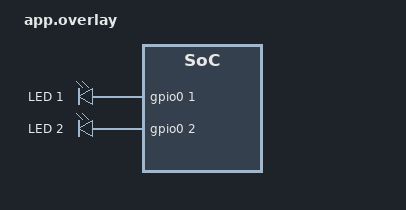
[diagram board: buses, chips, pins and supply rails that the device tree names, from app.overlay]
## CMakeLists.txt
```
# SPDX-License-Identifier: Apache-2.0

cmake_minimum_required(VERSION 3.28.0)

find_package(Zephyr REQUIRED HINTS $ENV{ZEPHYR_BASE})
project(projeto)

target_sources(app PRIVATE
	src/main.c
	src/led.c
)
```

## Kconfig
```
menu "LEDs"

config BLINK_SLOW_MS
	int "Periodo do pisca lento (ms)"
	default 1000

config BLINK_NORMAL_MS
	int "Periodo do pisca normal (ms)"
	default 400

config BLINK_FAST_MS
	int "Periodo do pisca rapido (ms)"
	default 100

endmenu

source "Kconfig.zephyr"
```

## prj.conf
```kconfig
CONFIG_GPIO=y
CONFIG_GPIO_EMUL=y
CONFIG_LOG=y
```

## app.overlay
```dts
/* led1 e led2 no gpio0, junto do led0 que ja vem na placa */

#include <zephyr/dt-bindings/gpio/gpio.h>

&leds {
	led1: led_1 {
		gpios = <&gpio0 1 GPIO_ACTIVE_HIGH>;
		label = "LED 1";
	};

	led2: led_2 {
		gpios = <&gpio0 2 GPIO_ACTIVE_HIGH>;
		label = "LED 2";
	};
};

/ {
	aliases {
		led1 = &led1;
		led2 = &led2;
	};
};
```

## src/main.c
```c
/*******************************************************************
 * @file main.c
 *
 * @brief Main file.
 * @author João Matheus Nascimento Dias (jmnd@ic.ufal.br)
 * @author Erick Mascarenhas (edlm@ic.ufal.br)
 * @version 0.1
 * @date 21/10/2026
 *******************************************************************/

#include <zephyr/kernel.h>
#include <zephyr/logging/log.h>

#include "led.h"

LOG_MODULE_REGISTER(main, CONFIG_LOG_DEFAULT_LEVEL);

int main(void)
{
	int ret;

	ret = led_init();
	if (ret < 0) {
		LOG_ERR("led_init falhou (%d)", ret);
		return 0;
	}

	LOG_INF("%zu LEDs prontos", led_count());

	ret = led_blink(0U, LED_PATTERN_SLOW);
	if (ret < 0) {
		LOG_ERR("led_blink(0) falhou (%d)", ret);
		return 0;
	}

	ret = led_blink(1U, LED_PATTERN_FAST);
	if (ret < 0) {
		LOG_ERR("led_blink(1) falhou (%d)", ret);
		return 0;
	}

	ret = led_on(2U);
	if (ret < 0) {
		LOG_ERR("led_on(2) falhou (%d)", ret);
		return 0;
	}

	LOG_INF("led0 lento, led1 rapido, led2 aceso");

	return 0;
}
```

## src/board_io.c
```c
/*******************************************************************
 * @file board_io.c
 *
 * @brief LED e botao da placa, obtidos do devicetree.
 * @author Erick Mascarenhas (edlm@ic.ufal.br)
 * @version 0.1
 * @date 21/10/2026
 *******************************************************************/

#include <errno.h>
#include <stdbool.h>

#include <zephyr/drivers/gpio.h>

#include "board_io.h"

static const struct gpio_dt_spec led = GPIO_DT_SPEC_GET(DT_ALIAS(led0), gpios);
static const struct gpio_dt_spec button = GPIO_DT_SPEC_GET(DT_ALIAS(sw0), gpios);

/* Guarda o estado do LED, ja que ler um pino de saida depende do driver */
static bool led_is_on;

int board_io_init(void)
{
	int ret;

	if (!gpio_is_ready_dt(&led) || !gpio_is_ready_dt(&button)) {
		return -ENODEV;
	}

	ret = gpio_pin_configure_dt(&led, GPIO_OUTPUT_INACTIVE);
	if (ret < 0) {
		return ret;
	}

	ret = gpio_pin_configure_dt(&button, GPIO_INPUT);
	if (ret < 0) {
		return ret;
	}

	led_is_on = false;

	return 0;
}

int board_io_led_set(bool on)
{
	int ret = gpio_pin_set_dt(&led, on);

	if (ret < 0) {
		return ret;
	}

	led_is_on = on;

	return 0;
}

bool board_io_led_get(void)
{
	return led_is_on;
}

int board_io_button_get(void)
{
	return gpio_pin_get_dt(&button);
}
```

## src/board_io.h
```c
/*******************************************************************
 * @file board_io.h
 *
 * @brief LED e botao da placa.
 * @author Erick Mascarenhas (edlm@ic.ufal.br)
 * @version 0.1
 * @date 21/10/2026
 *******************************************************************/

#ifndef BOARD_IO_H_
#define BOARD_IO_H_

#include <stdbool.h>

int board_io_init(void);
int board_io_led_set(bool on);
bool board_io_led_get(void);

/* 1 pressionado, 0 solto ou erro negativo */
int board_io_button_get(void);

#endif /* BOARD_IO_H_ */
```

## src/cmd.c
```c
/*******************************************************************
 * @file cmd.c
 *
 * @brief Interpretacao e despacho dos comandos da shell.
 * @author Erick Mascarenhas (edlm@ic.ufal.br)
 * @version 0.1
 * @date 21/10/2026
 *******************************************************************/

#include <errno.h>
#include <stdbool.h>
#include <stddef.h>
#include <stdio.h>

#include <zephyr/kernel.h>
#include <zephyr/sys/util.h>

#include "board_io.h"
#include "cmd.h"

typedef struct {
	const char *name;
	const char *usage;
	void (*handler)(const char *args, char *out, size_t out_size);
} cmd_entry_t;

static void cmd_help(const char *args, char *out, size_t out_size);
static void cmd_led(const char *args, char *out, size_t out_size);
static void cmd_btn(const char *args, char *out, size_t out_size);
static void cmd_uptime(const char *args, char *out, size_t out_size);
static void cmd_echo(const char *args, char *out, size_t out_size);

static const cmd_entry_t commands[] = {
	{.name = "HELP", .usage = "HELP - lista os comandos", .handler = cmd_help},
	{.name = "LED",
	 .usage = "LED [ON|OFF] - liga, desliga ou consulta o LED",
	 .handler = cmd_led},
	{.name = "BTN", .usage = "BTN - le o botao", .handler = cmd_btn},
	{.name = "UPTIME", .usage = "UPTIME - tempo desde o boot, em ms", .handler = cmd_uptime},
	{.name = "ECHO", .usage = "ECHO <texto> - devolve o texto", .handler = cmd_echo},
};

static char to_upper(char c)
{
	return ((c >= 'a') && (c <= 'z')) ? (char)(c - 'a' + 'A') : c;
}

static bool is_space(char c)
{
	return (c == ' ') || (c == '\t');
}

static const char *skip_spaces(const char *s)
{
	while (is_space(*s)) {
		s++;
	}

	return s;
}

static size_t token_len(const char *s)
{
	size_t n = 0U;

	while ((s[n] != '\0') && !is_space(s[n])) {
		n++;
	}

	return n;
}

/* compara sem diferenciar maiusculas, name ja vem em maiusculas */
static bool token_equals(const char *token, size_t len, const char *name)
{
	for (size_t i = 0U; i < len; i++) {
		if (to_upper(token[i]) != name[i]) {
			return false;
		}
	}

	return name[len] == '\0';
}

static void respond(char *out, size_t out_size, const char *text)
{
	(void)snprintf(out, out_size, "%s", text);
}

static void cmd_help(const char *args, char *out, size_t out_size)
{
	size_t used = 0U;

	ARG_UNUSED(args);

	for (size_t i = 0U; i < ARRAY_SIZE(commands); i++) {
		int written = snprintf(&out[used], out_size - used, "%s%s", (i == 0U) ? "" : "\r\n",
				       commands[i].usage);

		if ((written < 0) || ((size_t)written >= (out_size - used))) {
			break;
		}

		used += (size_t)written;
	}
}

static void cmd_led(const char *args, char *out, size_t out_size)
{
	size_t len = token_len(args);
	bool turn_on;

	if (len == 0U) {
		respond(out, out_size, board_io_led_get() ? "LED: ON" : "LED: OFF");
		return;
	}

	if (token_len(skip_spaces(&args[len])) != 0U) {
		respond(out, out_size, CMD_ERR_UNKNOWN);
		return;
	}

	if (token_equals(args, len, "ON")) {
		turn_on = true;
	} else if (token_equals(args, len, "OFF")) {
		turn_on = false;
	} else {
		respond(out, out_size, CMD_ERR_UNKNOWN);
		return;
	}

	respond(out, out_size, (board_io_led_set(turn_on) < 0) ? CMD_ERR_IO : "OK");
}

static void cmd_btn(const char *args, char *out, size_t out_size)
{
	int state;

	ARG_UNUSED(args);

	state = board_io_button_get();
	if (state < 0) {
		respond(out, out_size, CMD_ERR_IO);
		return;
	}

	(void)snprintf(out, out_size, "BTN: %d", state);
}

static void cmd_uptime(const char *args, char *out, size_t out_size)
{
	ARG_UNUSED(args);

	(void)snprintf(out, out_size, "UPTIME: %lld ms", (long long)k_uptime_get());
}

static void cmd_echo(const char *args, char *out, size_t out_size)
{
	respond(out, out_size, args);
}

int cmd_dispatch(const char *line, char *out, size_t out_size)
{
	const char *cursor;
	size_t name_len;

	if ((line == NULL) || (out == NULL) || (out_size == 0U)) {
		return -EINVAL;
	}

	out[0] = '\0';

	cursor = skip_spaces(line);
	name_len = token_len(cursor);

	/* linha vazia so devolve o prompt */
	if (name_len == 0U) {
		return 0;
	}

	for (size_t i = 0U; i < ARRAY_SIZE(commands); i++) {
		if (token_equals(cursor, name_len, commands[i].name)) {
			commands[i].handler(skip_spaces(&cursor[name_len]), out, out_size);
			return 0;
		}
	}

	respond(out, out_size, CMD_ERR_UNKNOWN);

	return -ENOENT;
}
```

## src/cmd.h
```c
/*******************************************************************
 * @file cmd.h
 *
 * @brief Interpretacao e despacho dos comandos da shell.
 * @author Erick Mascarenhas (edlm@ic.ufal.br)
 * @version 0.1
 * @date 21/10/2026
 *******************************************************************/

#ifndef CMD_H_
#define CMD_H_

#include <stddef.h>

#define CMD_ERR_UNKNOWN       "ERR: unknown command"
#define CMD_ERR_IO            "ERR: io error"
#define CMD_ERR_LINE_TOO_LONG "ERR: line too long"

/* Escreve em out a resposta para a linha, sem o \r\n final.
 * Retorna 0 se reconheceu o comando, -ENOENT se nao. */
int cmd_dispatch(const char *line, char *out, size_t out_size);

#endif /* CMD_H_ */
```

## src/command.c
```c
/*******************************************************************
 * @file command.c
 *
 * @brief Despachante genérico de comandos (Command Pattern).
 * @author Erick Mascarenhas (edlm@ic.ufal.br)
 * @version 0.1
 * @date 26/09/2026
 *******************************************************************/

#include <stddef.h>
#include <string.h>

#include "command.h"

command_status_t command_dispatch(const command_t *table, size_t count, const char *name)
{
	if (table == NULL || name == NULL) {
		return COMMAND_INVALID;
	}

	for (size_t i = 0; i < count; i++) {
		const command_t *entry = &table[i];

		if (entry->name == NULL || strcmp(entry->name, name) != 0) {
			continue;
		}

		if (entry->execute == NULL) {
			return COMMAND_INVALID;
		}

		entry->execute();

		return COMMAND_OK;
	}

	return COMMAND_NOT_FOUND;
}
```

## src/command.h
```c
/*******************************************************************
 * @file command.h
 *
 * @brief Interface genérica de comando (Command Pattern).
 * @author Erick Mascarenhas (edlm@ic.ufal.br)
 * @version 0.1
 * @date 26/09/2026
 *******************************************************************/

#ifndef COMMAND_H_
#define COMMAND_H_

#include <stddef.h>

/**
 * @brief Um comando que sabe executar a si mesmo.
 *
 * É tudo o que o despachante enxerga: um rótulo e uma ação. Qual ação é
 * essa, e o que ela faz por baixo, não interessa a quem despacha.
 */
typedef struct {
	/** Rótulo pelo qual o comando é invocado. */
	const char *name;
	/** Ação que o comando executa. */
	void (*execute)(void);
} command_t;

/** Resultado de uma tentativa de despacho. */
typedef enum {
	/** Comando encontrado e executado. */
	COMMAND_OK = 0,
	/** Nenhuma entrada da tabela corresponde ao rótulo pedido. */
	COMMAND_NOT_FOUND = -1,
	/** Argumento inválido, ou entrada da tabela sem ação. */
	COMMAND_INVALID = -2,
} command_status_t;

/**
 * @brief Procura @p name na tabela e executa o comando correspondente.
 *
 * Não conhece nenhum comando concreto: compara rótulos e chama o ponteiro
 * de função da entrada que casar. Comandos novos entram na tabela sem que
 * esta função precise mudar.
 *
 * @param table Tabela de comandos disponíveis.
 * @param count Número de entradas em @p table.
 * @param name Rótulo do comando pedido.
 *
 * @return COMMAND_OK, COMMAND_NOT_FOUND ou COMMAND_INVALID.
 */
command_status_t command_dispatch(const command_t *table, size_t count, const char *name);

#endif /* COMMAND_H_ */
```

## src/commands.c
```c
/*******************************************************************
 * @file commands.c
 *
 * @brief Comandos concretos e a tabela que os expõe.
 * @author Erick Mascarenhas (edlm@ic.ufal.br)
 * @version 0.1
 * @date 26/09/2026
 *******************************************************************/

#include <stdbool.h>
#include <stddef.h>

#include <zephyr/kernel.h>
#include <zephyr/sys/util.h>

#include "command.h"
#include "commands.h"

/** LED sobre o qual os comandos de acender e apagar atuam. */
static const char led_alvo[] = "verde";

/**
 * Acender e apagar diferem só pelo estado pedido, então compartilham a
 * implementação e cada comando entra na tabela como uma ação própria.
 */
static void led_set(bool on)
{
	printk("LED %s %s\n", led_alvo, on ? "aceso" : "apagado");
}

static void led_on_execute(void)
{
	led_set(true);
}

static void led_off_execute(void)
{
	led_set(false);
}

static void uptime_execute(void)
{
	printk("Uptime: %lld ms\n", k_uptime_get());
}

static void reboot_execute(void)
{
	printk("Reiniciando o sistema\n");
}

/**
 * Acrescentar um comando é acrescentar a ação acima e uma linha aqui. O
 * despachante em command.c não muda.
 */
static const command_t table[] = {
	{.name = "led_on", .execute = led_on_execute},
	{.name = "led_off", .execute = led_off_execute},
	{.name = "uptime", .execute = uptime_execute},
	{.name = "reboot", .execute = reboot_execute},
};

const command_t *commands_get_table(size_t *count)
{
	if (count == NULL) {
		return NULL;
	}

	*count = ARRAY_SIZE(table);

	return table;
}
```

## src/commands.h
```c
/*******************************************************************
 * @file commands.h
 *
 * @brief Tabela dos comandos concretos da aplicação.
 * @author Erick Mascarenhas (edlm@ic.ufal.br)
 * @version 0.1
 * @date 26/09/2026
 *******************************************************************/

#ifndef COMMANDS_H_
#define COMMANDS_H_

#include <stddef.h>

#include "command.h"

/**
 * @brief Entrega a tabela de comandos concretos disponíveis.
 *
 * @param count Recebe o número de entradas da tabela.
 *
 * @return Ponteiro para a tabela, ou NULL se @p count for NULL.
 */
const command_t *commands_get_table(size_t *count);

#endif /* COMMANDS_H_ */
```

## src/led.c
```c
/*******************************************************************
 * @file led.c
 *
 * @brief Modulo de LEDs com pisca independente usando um unico timer.
 * @author Erick Mascarenhas (edlm@ic.ufal.br)
 * @version 0.1
 * @date 21/10/2026
 *******************************************************************/

#include <errno.h>
#include <stdbool.h>
#include <stdint.h>

#include <zephyr/drivers/gpio.h>
#include <zephyr/kernel.h>
#include <zephyr/logging/log.h>
#include <zephyr/sys/util.h>

#include "led.h"

LOG_MODULE_REGISTER(led, CONFIG_LOG_DEFAULT_LEVEL);

#define LED_SPEC(alias) GPIO_DT_SPEC_GET(DT_ALIAS(alias), gpios)

static const struct gpio_dt_spec leds[] = {
	LED_SPEC(led0),
	LED_SPEC(led1),
	LED_SPEC(led2),
};

static const uint32_t pattern_ms[LED_PATTERN_COUNT] = {
	[LED_PATTERN_SLOW] = CONFIG_BLINK_SLOW_MS,
	[LED_PATTERN_NORMAL] = CONFIG_BLINK_NORMAL_MS,
	[LED_PATTERN_FAST] = CONFIG_BLINK_FAST_MS,
};

typedef struct {
	bool blinking;
	uint32_t period_ms;
	int64_t deadline;
} led_state_t;

typedef int (*led_action_t)(size_t led, uint32_t arg);

static led_state_t states[ARRAY_SIZE(leds)];
static struct k_spinlock lock;
static bool ready;

static void blink_expiry(struct k_timer *timer);

static K_TIMER_DEFINE(blink_timer, blink_expiry, NULL);

/* arma o timer (one-shot) para o prazo mais proximo; chamar com o lock */
static void rearm_locked(void)
{
	int64_t now = k_uptime_get();
	int64_t next = INT64_MAX;

	for (size_t i = 0U; i < ARRAY_SIZE(leds); i++) {
		if (states[i].blinking && (states[i].deadline < next)) {
			next = states[i].deadline;
		}
	}

	if (next == INT64_MAX) {
		k_timer_stop(&blink_timer);
		return;
	}

	k_timer_start(&blink_timer, K_MSEC(MAX(next - now, (int64_t)1)), K_NO_WAIT);
}

/* contexto de ISR: so GPIO, prazos e rearme */
static void blink_expiry(struct k_timer *timer)
{
	k_spinlock_key_t key;
	int64_t now;

	ARG_UNUSED(timer);

	key = k_spin_lock(&lock);
	now = k_uptime_get();

	for (size_t i = 0U; i < ARRAY_SIZE(leds); i++) {
		if (!states[i].blinking || (now < states[i].deadline)) {
			continue;
		}

		(void)gpio_pin_toggle_dt(&leds[i]);

		states[i].deadline += states[i].period_ms;
		if (states[i].deadline <= now) {
			states[i].deadline = now + states[i].period_ms;
		}
	}

	rearm_locked();
	k_spin_unlock(&lock, key);
}

static int action_on(size_t led, uint32_t arg)
{
	ARG_UNUSED(arg);

	states[led].blinking = false;

	return gpio_pin_set_dt(&leds[led], 1);
}

static int action_off(size_t led, uint32_t arg)
{
	ARG_UNUSED(arg);

	states[led].blinking = false;

	return gpio_pin_set_dt(&leds[led], 0);
}

static int action_toggle(size_t led, uint32_t arg)
{
	ARG_UNUSED(arg);

	states[led].blinking = false;

	return gpio_pin_toggle_dt(&leds[led]);
}

static int action_blink(size_t led, uint32_t pattern)
{
	states[led].period_ms = pattern_ms[pattern];
	states[led].deadline = k_uptime_get() + (int64_t)states[led].period_ms;
	states[led].blinking = true;

	return 0;
}

/* aplica a acao a um LED ou a todos (LED_ALL) */
static int led_apply(size_t led, led_action_t action, uint32_t arg)
{
	k_spinlock_key_t key;
	int ret = 0;

	if (!ready) {
		LOG_ERR("modulo nao inicializado");
		return -ENODEV;
	}

	if ((led != LED_ALL) && (led >= ARRAY_SIZE(leds))) {
		LOG_ERR("LED %zu invalido", led);
		return -EINVAL;
	}

	key = k_spin_lock(&lock);

	if (led == LED_ALL) {
		for (size_t i = 0U; i < ARRAY_SIZE(leds); i++) {
			int err = action(i, arg);

			if (err < 0) {
				ret = err;
			}
		}
	} else {
		ret = action(led, arg);
	}

	rearm_locked();
	k_spin_unlock(&lock, key);

	return ret;
}

int led_init(void)
{
	k_spinlock_key_t key;

	for (size_t i = 0U; i < ARRAY_SIZE(leds); i++) {
		if (!gpio_is_ready_dt(&leds[i])) {
			LOG_ERR("controlador do LED %zu nao esta pronto", i);
			return -ENODEV;
		}
	}

	/* para o timer antes de mexer no estado, por causa do reinit */
	k_timer_stop(&blink_timer);

	key = k_spin_lock(&lock);

	for (size_t i = 0U; i < ARRAY_SIZE(leds); i++) {
		int ret = gpio_pin_configure_dt(&leds[i], GPIO_OUTPUT_INACTIVE);

		if (ret < 0) {
			k_spin_unlock(&lock, key);
			LOG_ERR("falha ao configurar o LED %zu (%d)", i, ret);
			return ret;
		}

		states[i].blinking = false;
		states[i].period_ms = 0U;
		states[i].deadline = 0;
	}

	ready = true;
	k_spin_unlock(&lock, key);

	return 0;
}

int led_on(size_t led)
{
	return led_apply(led, action_on, 0U);
}

int led_off(size_t led)
{
	return led_apply(led, action_off, 0U);
}

int led_toggle(size_t led)
{
	return led_apply(led, action_toggle, 0U);
}

int led_blink(size_t led, led_pattern_t pattern)
{
	if ((unsigned int)pattern >= (unsigned int)LED_PATTERN_COUNT) {
		LOG_ERR("padrao %u invalido", (unsigned int)pattern);
		return -EINVAL;
	}

	return led_apply(led, action_blink, (uint32_t)pattern);
}

size_t led_count(void)
{
	return ARRAY_SIZE(leds);
}
```

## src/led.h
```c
/*******************************************************************
 * @file led.h
 *
 * @brief Modulo de LEDs com pisca independente usando um unico timer.
 * @author Erick Mascarenhas (edlm@ic.ufal.br)
 * @version 0.1
 * @date 21/10/2026
 *******************************************************************/

#ifndef LED_H_
#define LED_H_

#include <stddef.h>

typedef enum {
	LED_PATTERN_SLOW = 0,
	LED_PATTERN_NORMAL,
	LED_PATTERN_FAST,
	LED_PATTERN_COUNT,
} led_pattern_t;

/* usar no lugar do indice para aplicar a todos os LEDs */
#define LED_ALL ((size_t) - 1)

int led_init(void);
int led_on(size_t led);
int led_off(size_t led);
int led_toggle(size_t led);
int led_blink(size_t led, led_pattern_t pattern);
size_t led_count(void);

#endif /* LED_H_ */
```

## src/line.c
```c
/*******************************************************************
 * @file line.c
 *
 * @brief Montagem da linha de comando byte a byte.
 * @author Erick Mascarenhas (edlm@ic.ufal.br)
 * @version 0.1
 * @date 21/10/2026
 *******************************************************************/

#include <stdbool.h>
#include <stddef.h>

#include "line.h"

#define ASCII_BACKSPACE 0x08
#define ASCII_DELETE    0x7F

static bool is_terminator(char c)
{
	return (c == '\n') || (c == '\r');
}

static bool is_erase(char c)
{
	return (c == ASCII_BACKSPACE) || (c == ASCII_DELETE);
}

void line_reset(line_t *line)
{
	line->len = 0U;
	line->discarding = false;
	line->buf[0] = '\0';
}

line_event_t line_feed(line_t *line, char c)
{
	if (is_terminator(c)) {
		line->buf[line->len] = '\0';

		if (line->discarding) {
			line_reset(line);
			return LINE_EVENT_OVERFLOW;
		}

		return LINE_EVENT_READY;
	}

	/* linha estourada: ignora tudo ate o fim dela */
	if (line->discarding) {
		return LINE_EVENT_NONE;
	}

	if (is_erase(c)) {
		if (line->len == 0U) {
			return LINE_EVENT_NONE;
		}

		line->len--;
		line->buf[line->len] = '\0';

		return LINE_EVENT_ERASE;
	}

	if (line->len >= CONFIG_MINISHELL_LINE_SIZE) {
		line->discarding = true;
		return LINE_EVENT_NONE;
	}

	line->buf[line->len] = c;
	line->len++;
	line->buf[line->len] = '\0';

	return LINE_EVENT_ECHO;
}

const char *line_str(const line_t *line)
{
	return line->buf;
}
```

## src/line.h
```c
/*******************************************************************
 * @file line.h
 *
 * @brief Montagem da linha de comando byte a byte.
 * @author Erick Mascarenhas (edlm@ic.ufal.br)
 * @version 0.1
 * @date 21/10/2026
 *******************************************************************/

#ifndef LINE_H_
#define LINE_H_

#include <stdbool.h>
#include <stddef.h>

#include <zephyr/kernel.h>

typedef enum {
	LINE_EVENT_NONE = 0,
	LINE_EVENT_ECHO,
	LINE_EVENT_ERASE,
	LINE_EVENT_READY,
	LINE_EVENT_OVERFLOW,
} line_event_t;

typedef struct {
	char buf[CONFIG_MINISHELL_LINE_SIZE + 1];
	size_t len;
	bool discarding;
} line_t;

void line_reset(line_t *line);
line_event_t line_feed(line_t *line, char c);
const char *line_str(const line_t *line);

#endif /* LINE_H_ */
```
